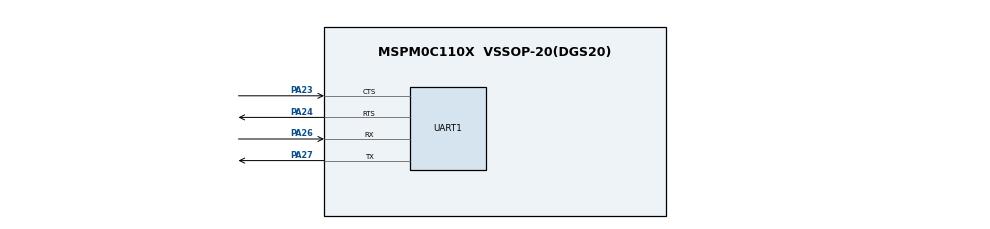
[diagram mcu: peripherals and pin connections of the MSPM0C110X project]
/**
 * @versions {"tool":"1.0.0+dev"}
 */
// @cliArgs --device "MSPM0C110X" --package "VSSOP-20(DGS20)" --part "Default"
// @cliArgs --board /ti/boards/LP_MSPM0C1104 --rtos nortos

/**
 * Import the modules used in this configuration.
 */
const UART   = scripting.addModule("/ti/driverlib/UART", {}, false);
const UART1  = UART.addInstance();

/**
 * Write custom configuration values to the imported modules.
 */

UART1.$name = "UART_0";
UART1.profile = "CONFIG_PROFILE_3";
UART1.targetBaudRate = 115200;
UART1.enableFIFO = true;
UART1.peripheral.$assign = "UART0";

UART1.peripheral.txPin.$assign = "PA27";
UART1.peripheral.rxPin.$assign = "PA26";
UART1.peripheral.rtsPin.$assign = "PA24";
UART1.peripheral.ctsPin.$assign = "PA23";
